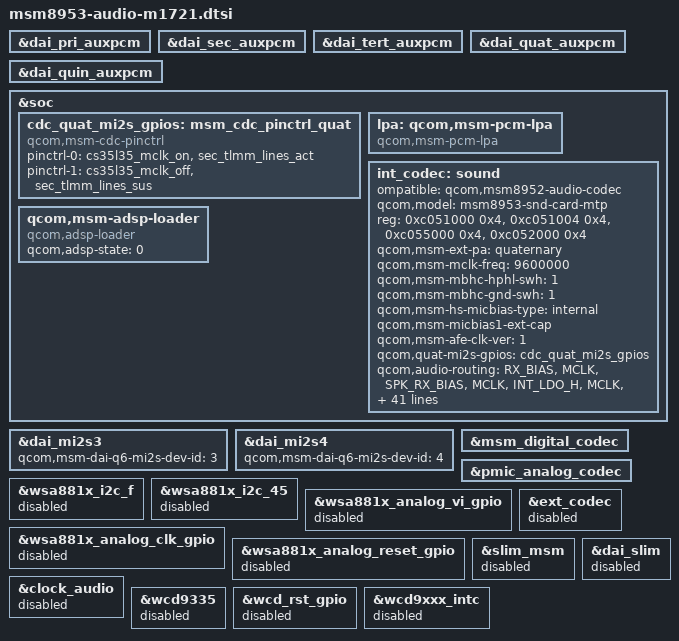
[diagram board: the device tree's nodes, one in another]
/*
 * Copyright (c) 2017, The Linux Foundation. All rights reserved.
 *
 * This program is free software; you can redistribute it and/or modify
 * it under the terms of the GNU General Public License version 2 and
 * only version 2 as published by the Free Software Foundation.
 *
 * This program is distributed in the hope that it will be useful,
 * but WITHOUT ANY WARRANTY; without even the implied warranty of
 * MERCHANTABILITY or FITNESS FOR A PARTICULAR PURPOSE.  See the
 * GNU General Public License for more details.
 */

&dai_pri_auxpcm {
    /delete-property/ qcom,msm-cpudai-afe-clk-ver;
};

&dai_sec_auxpcm {
    /delete-property/ qcom,msm-cpudai-afe-clk-ver;
};

&dai_tert_auxpcm {
    /delete-property/ qcom,msm-cpudai-afe-clk-ver;
};

&dai_quat_auxpcm {
    /delete-property/ qcom,msm-cpudai-afe-clk-ver;
};

&dai_quin_auxpcm {
    /delete-property/ qcom,msm-cpudai-afe-clk-ver;
};

&soc {
	cdc_quat_mi2s_gpios: msm_cdc_pinctrl_quat {
		compatible = "qcom,msm-cdc-pinctrl";
		pinctrl-names = "aud_active", "aud_sleep";
		pinctrl-0 = <&cs35l35_mclk_on &sec_tlmm_lines_act>;
		pinctrl-1 = <&cs35l35_mclk_off &sec_tlmm_lines_sus>;
	};

	lpa: qcom,msm-pcm-lpa {
		compatible = "qcom,msm-pcm-lpa";
	};

	int_codec: sound {
		status = "ok";
		ompatible = "qcom,msm8952-audio-codec";
		qcom,model = "msm8953-snd-card-mtp";
		reg = <0xc051000 0x4>,
			<0xc051004 0x4>,
			<0xc055000 0x4>,
			<0xc052000 0x4>;
		reg-names = "csr_gp_io_mux_mic_ctl",
			"csr_gp_io_mux_spkr_ctl",
			"csr_gp_io_lpaif_pri_pcm_pri_mode_muxsel",
			"csr_gp_io_mux_quin_ctl";

		qcom,msm-ext-pa = "quaternary";
		qcom,msm-mclk-freq = <9600000>;
		qcom,msm-mbhc-hphl-swh = <1>;
		qcom,msm-mbhc-gnd-swh = <1>;
		qcom,msm-hs-micbias-type = "internal";
		qcom,msm-micbias1-ext-cap;
		qcom,msm-afe-clk-ver = <1>;

		qcom,quat-mi2s-gpios = <&cdc_quat_mi2s_gpios>;

		qcom,audio-routing =
			"RX_BIAS", "MCLK",
			"SPK_RX_BIAS", "MCLK",
			"INT_LDO_H", "MCLK",
			"MIC BIAS External", "Handset Mic",
			"MIC BIAS External2", "Headset Mic",
			"MIC BIAS External", "Secondary Mic",
			"AMIC1", "MIC BIAS External",
			"AMIC2", "MIC BIAS External2",
			"AMIC3", "MIC BIAS External",
			"WSA_SPK OUT", "VDD_WSA_SWITCH",
			"SpkrMono WSA_IN", "WSA_SPK OUT";

		asoc-cpu = <&dai_pri_auxpcm>,
				<&dai_mi2s0>, <&dai_mi2s1>,
				<&dai_mi2s2>, <&dai_mi2s3>,
				<&dai_mi2s4>, <&dai_mi2s5>,
				<&sb_0_rx>, <&sb_0_tx>, <&sb_1_rx>, <&sb_1_tx>,
				<&sb_3_rx>, <&sb_3_tx>, <&sb_4_rx>, <&sb_4_tx>,
				<&bt_sco_rx>, <&bt_sco_tx>,
				<&int_fm_rx>, <&int_fm_tx>,
				<&afe_pcm_rx>, <&afe_pcm_tx>,
				<&afe_proxy_rx>, <&afe_proxy_tx>,
				<&incall_record_rx>, <&incall_record_tx>,
				<&incall_music_rx>, <&incall_music_2_rx>,
				<&proxy_rx>, <&proxy_tx>;

		asoc-cpu-names = "msm-dai-q6-auxpcm.1",
				"msm-dai-q6-mi2s.0", "msm-dai-q6-mi2s.1",
				"msm-dai-q6-mi2s.2", "msm-dai-q6-mi2s.3",
				"msm-dai-q6-mi2s.4", "msm-dai-q6-mi2s.6",
				"msm-dai-q6-dev.16384", "msm-dai-q6-dev.16385",
				"msm-dai-q6-dev.16386", "msm-dai-q6-dev.16387",
				"msm-dai-q6-dev.16390", "msm-dai-q6-dev.16391",
				"msm-dai-q6-dev.16392", "msm-dai-q6-dev.16393",
				"msm-dai-q6-dev.12288", "msm-dai-q6-dev.12289",
				"msm-dai-q6-dev.12292", "msm-dai-q6-dev.12293",
				"msm-dai-q6-dev.224", "msm-dai-q6-dev.225",
				"msm-dai-q6-dev.241", "msm-dai-q6-dev.240",
				"msm-dai-q6-dev.32771", "msm-dai-q6-dev.32772",
				"msm-dai-q6-dev.32773", "msm-dai-q6-dev.32770",
				"msm-dai-q6-dev.8194", "msm-dai-q6-dev.8195";

		asoc-platform = <&pcm0>, <&pcm1>, <&pcm2>, <&voip>, <&voice>,
				<&loopback>, <&compress>, <&hostless>,
				<&afe>, <&lsm>, <&routing>, <&lpa>, <&pcm_noirq>;
		asoc-platform-names = "msm-pcm-dsp.0", "msm-pcm-dsp.1",
				"msm-pcm-dsp.2", "msm-voip-dsp",
				"msm-pcm-voice", "msm-pcm-loopback",
				"msm-compress-dsp", "msm-pcm-hostless",
				"msm-pcm-afe", "msm-lsm-client",
				"msm-pcm-routing", "msm-pcm-lpa",
				"msm-pcm-dsp-noirq";

		/delete-property/ asoc-wsa-codec-names;
		/delete-property/ asoc-wsa-codec-prefixes;
		/delete-property/ qcom,hdmi-dba-codec-rx;
		/delete-property/ qcom,msm-dai-q6-hdmi;
		/delete-property/ msm-vdd-wsa-switch-supply;
		/delete-property/ qcom,msm-vdd-wsa-switch-voltage;
		/delete-property/ qcom,msm-vdd-wsa-switch-current;
	};

	qcom,msm-adsp-loader {
		/delete-property/ status;
		compatible = "qcom,adsp-loader";
		qcom,adsp-state = <0>;
	};
};

&dai_mi2s3 {
	qcom,msm-dai-q6-mi2s-dev-id = <3>;
};

&dai_mi2s4 {
	qcom,msm-dai-q6-mi2s-dev-id = <4>;
};

&msm_digital_codec {
		status = "okay";
};

&pmic_analog_codec {
		status = "okay";
};

&wsa881x_i2c_f {
        status = "disabled";
};

&wsa881x_i2c_45 {
        status = "disabled";
};

&wsa881x_analog_vi_gpio {
        status = "disabled";
};

&wsa881x_analog_clk_gpio {
        status = "disabled";
};

&wsa881x_analog_reset_gpio {
        status = "disabled";
};

&ext_codec {
		status = "disabled";
};

&slim_msm {
		status = "disabled";
};

&dai_slim {
		status = "disabled";
};

&clock_audio {
		status = "disabled";
};

&wcd9335 {
		status = "disabled";
};

&wcd_rst_gpio {
		status = "disabled";
};

&wcd9xxx_intc {
		status = "disabled";
};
